# STM32U3C5 register map
File version: 1.0
CPU: CM33 r0p1, little endian, MPU, FPU, 4 interrupt priority bits
Registers are 32-bit, read-write, reset 0x0 unless marked. A register's access mark holds for its fields unless they carry their own. Offsets are from the block's base; [hi:lo] are bit positions; {n}, {i} and the like mark numbered series; 'fields as' and 'values as' point back to an identical list.

## GTZC1_MPCBB3 — GTZC1_MPCBB3 address block description
Base 0x40033400
Same registers: SEC_GTZC1_MPCBB3 0x50033400
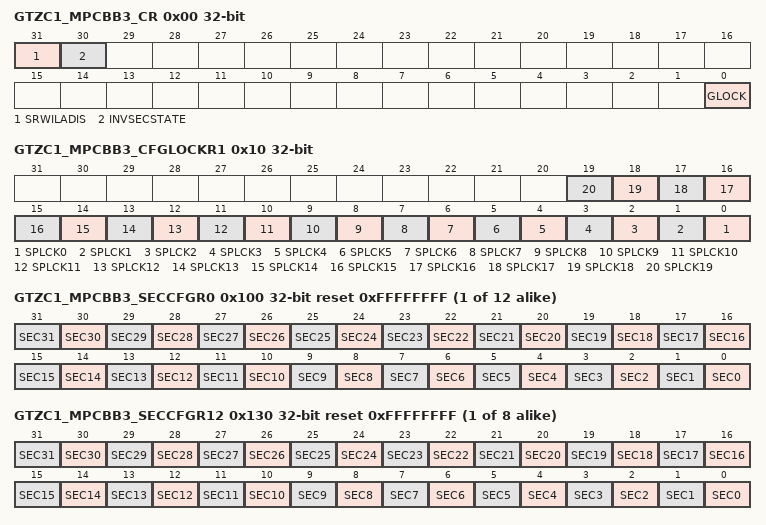
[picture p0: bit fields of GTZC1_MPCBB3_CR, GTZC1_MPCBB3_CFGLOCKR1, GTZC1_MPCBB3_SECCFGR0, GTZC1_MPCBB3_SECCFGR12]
0x00 GTZC1_MPCBB3_CR (alternate view of GTZC1_TZSC_CR) — GTZC1 SRAM3 MPCBB control register
  [31] SRWILADIS — Secure read/write illegal access disable
    0=Enabled, secure read/write access not allowed on nonsecure SRAM block; 1=Disabled, secure read/write access allowed on nonsecure SRAM block
  [30] INVSECSTATE — SRAM3 clock security state
    0=SRAM clocks are secure if a secure area exists in the MPCBB, and nonsecure if there is no secure area; 1=SRAM clocks are nonsecure even if a secure area exists in the MPCBB, and secure even if no secure block is set in the MPCBB
  [0] GLOCK — Lock the control register of the MPCBB until next reset
    0=Control register not locked; 1=Control register locked
0x10 GTZC1_MPCBB3_CFGLOCKR1 (alternate view of GTZC1_TZSC_SECCFGR1) — GTZC1 SRAM3 MPCBB configuration lock register 1
  [all] fields
    0=GTZC1_MPCBB3_SECCFGRi and GTZC1_MPCBB3_PRIVCFGRi can be written; 1=Writes to GTZC1_MPCBB3_SECCFGRi and GTZC1_MPCBB3_PRIVCFGRi are ignored
  [n] SPLCK{n} (n=0..19) — Security/privilege configuration lock for super-block i
{0x100+4i} GTZC1_MPCBB3_SECCFGR{i} reset 0xFFFFFFFF (alternate view of GTZC1_MPCBB1_SECCFGR{i}) (i=0..11) — GTZC1 SRAM3 MPCBB security configuration for super-block {i} register
  [all] fields
    0=Nonsecure access only to block i, belonging to super-block x; 1=Secure access only to block i, belonging to super-block x
  [n] SEC{n} (n=0..31) — Security configuration for block i
{0x100+4i} GTZC1_MPCBB3_SECCFGR{i} reset 0xFFFFFFFF (i=12..19) — GTZC1 SRAM3 MPCBB security configuration for super-block {i} register
  fields as GTZC1_MPCBB3_SECCFGR0
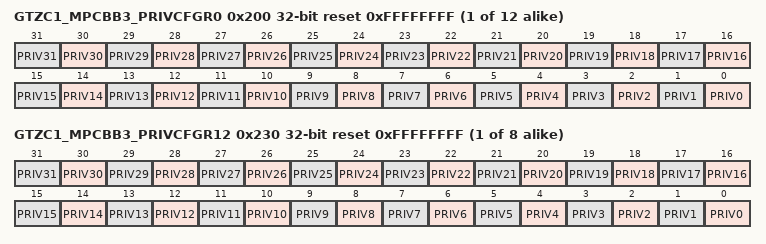
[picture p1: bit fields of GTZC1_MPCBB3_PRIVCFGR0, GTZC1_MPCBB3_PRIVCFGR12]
{0x200+4i} GTZC1_MPCBB3_PRIVCFGR{i} reset 0xFFFFFFFF (alternate view of GTZC1_MPCBB1_PRIVCFGR{i}) (i=0..11) — GTZC1 SRAM3 MPCBB privileged configuration for super-block {i} register
  [all] fields
    0=Privileged and unprivileged access to block i, belonging to super-block x; 1=Only privileged access to block i, belonging to super-block x
  [n] PRIV{n} (n=0..31) — Privileged configuration for block i, belonging to super-block x
{0x200+4i} GTZC1_MPCBB3_PRIVCFGR{i} reset 0xFFFFFFFF (i=12..19) — GTZC1 SRAM3 MPCBB privileged configuration for super-block {i} register
  fields as GTZC1_MPCBB3_PRIVCFGR0

## GTZC1_MPCBB4 — GTZC1_MPCBB4 address block description
Base 0x40033800
Same registers: SEC_GTZC1_MPCBB4 0x50033800
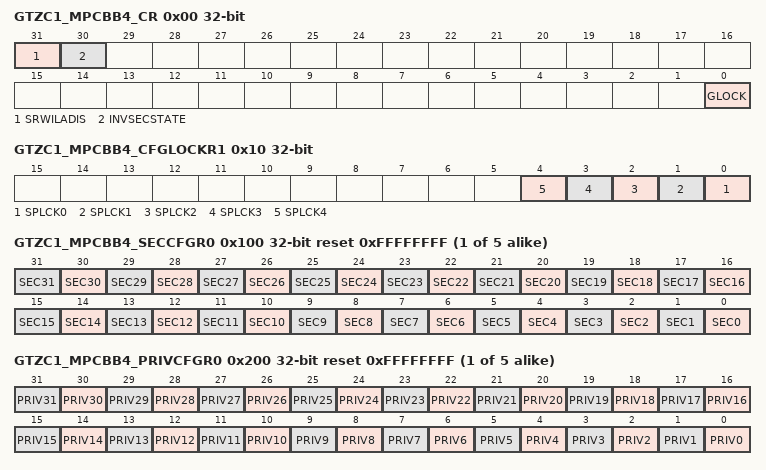
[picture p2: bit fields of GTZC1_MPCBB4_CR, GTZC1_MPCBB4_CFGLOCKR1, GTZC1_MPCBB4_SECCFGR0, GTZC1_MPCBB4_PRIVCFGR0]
0x00 GTZC1_MPCBB4_CR (alternate view of GTZC1_TZSC_CR) — GTZC1 SRAM4 MPCBB control register
  [31] SRWILADIS — Secure read/write illegal access disable
    0=Enabled, secure read/write access not allowed on nonsecure SRAM block; 1=Disabled, secure read/write access allowed on nonsecure SRAM block
  [30] INVSECSTATE — SRAM4 clock security state
    0=SRAM clocks are secure if a secure area exists in the MPCBB, and nonsecure if there is no secure area; 1=SRAM clocks are nonsecure even if a secure area exists in the MPCBB, and secure even if no secure block is set in the MPCBB
  [0] GLOCK — Lock the control register of the MPCBB until next reset
    0=Control register not locked; 1=Control register locked
0x10 GTZC1_MPCBB4_CFGLOCKR1 (alternate view of GTZC1_TZSC_SECCFGR1) — GTZC1 SRAM4 MPCBB configuration lock register 1
  [all] fields
    0=GTZC1_MPCBB4_SECCFGRi and GTZC1_MPCBB4_PRIVCFGRi can be written; 1=Writes to GTZC1_MPCBB4_SECCFGRi and GTZC1_MPCBB4_PRIVCFGRi are ignored
  [n] SPLCK{n} (n=0..4) — Security/privilege configuration lock for super-block i
{0x100+4i} GTZC1_MPCBB4_SECCFGR{i} reset 0xFFFFFFFF (alternate view of GTZC1_MPCBB1_SECCFGR{i}) (i=0..4) — GTZC1 SRAM4 MPCBB security configuration for super-block {i} register
  [all] fields
    0=Nonsecure access only to block i, belonging to super-block x; 1=Secure access only to block i, belonging to super-block x
  [n] SEC{n} (n=0..31) — Security configuration for block i
{0x200+4i} GTZC1_MPCBB4_PRIVCFGR{i} reset 0xFFFFFFFF (alternate view of GTZC1_MPCBB1_PRIVCFGR{i}) (i=0..4) — GTZC1 SRAM4 MPCBB privileged configuration for super-block {i} register
  [all] fields
    0=Privileged and unprivileged access to block i, belonging to super-block x; 1=Only privileged access to block i, belonging to super-block x
  [n] PRIV{n} (n=0..31) — Privileged configuration for block i, belonging to super-block x
